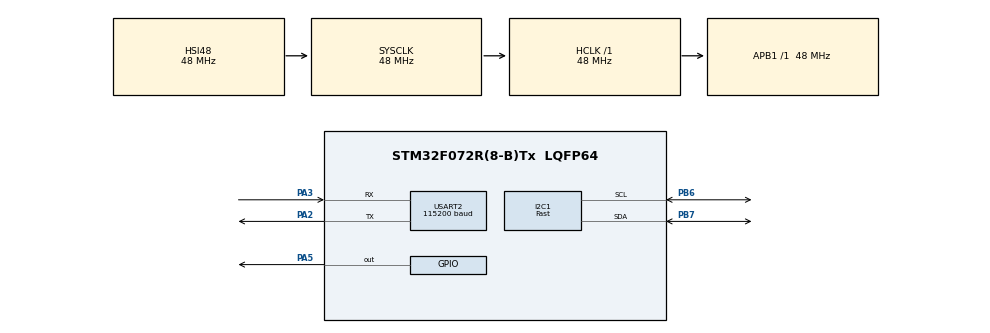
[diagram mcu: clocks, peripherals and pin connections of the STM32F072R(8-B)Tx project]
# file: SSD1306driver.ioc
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Dma.I2C1_RX.2.Direction=DMA_PERIPH_TO_MEMORY
Dma.I2C1_RX.2.Instance=DMA1_Channel3
Dma.I2C1_RX.2.MemDataAlignment=DMA_MDATAALIGN_BYTE
Dma.I2C1_RX.2.MemInc=DMA_MINC_ENABLE
Dma.I2C1_RX.2.Mode=DMA_NORMAL
Dma.I2C1_RX.2.PeriphDataAlignment=DMA_PDATAALIGN_BYTE
Dma.I2C1_RX.2.PeriphInc=DMA_PINC_DISABLE
Dma.I2C1_RX.2.Priority=DMA_PRIORITY_LOW
Dma.I2C1_TX.1.Direction=DMA_MEMORY_TO_PERIPH
Dma.I2C1_TX.1.Instance=DMA1_Channel2
Dma.I2C1_TX.1.MemDataAlignment=DMA_MDATAALIGN_BYTE
Dma.I2C1_TX.1.MemInc=DMA_MINC_ENABLE
Dma.I2C1_TX.1.Mode=DMA_NORMAL
Dma.I2C1_TX.1.PeriphDataAlignment=DMA_PDATAALIGN_BYTE
Dma.I2C1_TX.1.PeriphInc=DMA_PINC_DISABLE
Dma.I2C1_TX.1.Priority=DMA_PRIORITY_LOW
Dma.Request0=USART2_RX
Dma.Request1=I2C1_TX
Dma.Request2=I2C1_RX
Dma.USART2_RX.0.Direction=DMA_PERIPH_TO_MEMORY
Dma.USART2_RX.0.Instance=DMA1_Channel5
Dma.USART2_RX.0.MemDataAlignment=DMA_MDATAALIGN_BYTE
Dma.USART2_RX.0.MemInc=DMA_MINC_ENABLE
Dma.USART2_RX.0.Mode=DMA_NORMAL
Dma.USART2_RX.0.PeriphDataAlignment=DMA_PDATAALIGN_BYTE
Dma.USART2_RX.0.PeriphInc=DMA_PINC_DISABLE
Dma.USART2_RX.0.Priority=DMA_PRIORITY_LOW
I2C1.I2C_Speed_Mode=I2C_Fast
I2C1.Timing=0x0000020B
Mcu.Family=STM32F0
Mcu.Name=STM32F072R(8-B)Tx
Mcu.Package=LQFP64
NVIC.DMA1_Channel2_3_IRQn=true\:0\:0\:false\:false\:true\:false\:true
NVIC.DMA1_Channel4_5_6_7_IRQn=true\:0\:0\:false\:false\:true\:false\:true
NVIC.USART2_IRQn=true\:0\:0\:false\:false\:true\:true\:true
PA2.Mode=Asynchronous
PA2.Signal=USART2_TX
PA3.Mode=Asynchronous
PA3.Signal=USART2_RX
PA5.Signal=GPIO_Output
PB6.GPIO_FM6=SYSCFG_CFGR1_I2C_FMP_PB6
PB6.Mode=I2C
PB6.Signal=I2C1_SCL
PB7.GPIO_FM7=SYSCFG_CFGR1_I2C_FMP_PB7
PB7.Mode=I2C
PB7.Signal=I2C1_SDA
ProjectManager.HeapSize=0x200
ProjectManager.StackSize=0x400
ProjectManager.TargetToolchain=Makefile
RCC.AHBFreq_Value=48000000
RCC.APB1Freq_Value=48000000
RCC.APB1TimFreq_Value=48000000
RCC.HCLKFreq_Value=48000000
RCC.SYSCLKFreq_VALUE=48000000
RCC.SYSCLKSource=RCC_SYSCLKSOURCE_HSI48
USART2.BaudRate=115200
USART2.VirtualMode-Asynchronous=VM_ASYNC
board=custom

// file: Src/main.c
/* USER CODE BEGIN Header */
/**
	******************************************************************************
	* @file           : main.c
	* @brief          : Main program body
	******************************************************************************
	* @attention
	*
	* <h2><center>&copy; Copyright (c) 2020 STMicroelectronics.
	* All rights reserved.</center></h2>
	*
	* This software component is licensed by ST under BSD 3-Clause license,
	* the "License"; You may not use this file except in compliance with the
	* License. You may obtain a copy of the License at:
	*                        opensource.org/licenses/BSD-3-Clause
	*
	******************************************************************************
	*/
/* USER CODE END Header */

#include "main.h"

I2C_HandleTypeDef hi2c1;
DMA_HandleTypeDef hdma_i2c1_tx;
DMA_HandleTypeDef hdma_i2c1_rx;

UART_HandleTypeDef huart2;
DMA_HandleTypeDef hdma_usart2_rx;

void SystemClock_Config(void);
static void MX_GPIO_Init(void);
static void MX_DMA_Init(void);
static void MX_I2C1_Init(void);
static void MX_USART2_UART_Init(void);

int main(void)
{

  /* MCU Configuration--------------------------------------------------------*/

  /* Reset of all peripherals, Initializes the Flash interface and the Systick. */
  HAL_Init();

  /* Configure the system clock */
  SystemClock_Config();

  /* Initialize all configured peripherals */
  MX_GPIO_Init();
  MX_DMA_Init();
  MX_I2C1_Init();
  MX_USART2_UART_Init();
  /* USER CODE BEGIN 2 */
  SSD1306_init(&hi2c1);
  /* USER CODE END 2 */

  /* Infinite loop */
	while (1)
	{

	}
}

void SystemClock_Config(void)
{
  RCC_OscInitTypeDef RCC_OscInitStruct = {0};
  RCC_ClkInitTypeDef RCC_ClkInitStruct = {0};
  RCC_PeriphCLKInitTypeDef PeriphClkInit = {0};

  /** Initializes the CPU, AHB and APB busses clocks
  */
  RCC_OscInitStruct.OscillatorType = RCC_OSCILLATORTYPE_HSI|RCC_OSCILLATORTYPE_HSI48;
  RCC_OscInitStruct.HSIState = RCC_HSI_ON;
  RCC_OscInitStruct.HSI48State = RCC_HSI48_ON;
  RCC_OscInitStruct.HSICalibrationValue = RCC_HSICALIBRATION_DEFAULT;
  RCC_OscInitStruct.PLL.PLLState = RCC_PLL_NONE;
  if (HAL_RCC_OscConfig(&RCC_OscInitStruct) != HAL_OK)
  {
    Error_Handler();
  }
  /** Initializes the CPU, AHB and APB busses clocks
  */
  RCC_ClkInitStruct.ClockType = RCC_CLOCKTYPE_HCLK|RCC_CLOCKTYPE_SYSCLK
                              |RCC_CLOCKTYPE_PCLK1;
  RCC_ClkInitStruct.SYSCLKSource = RCC_SYSCLKSOURCE_HSI48;
  RCC_ClkInitStruct.AHBCLKDivider = RCC_SYSCLK_DIV1;
  RCC_ClkInitStruct.APB1CLKDivider = RCC_HCLK_DIV1;

  if (HAL_RCC_ClockConfig(&RCC_ClkInitStruct, FLASH_LATENCY_1) != HAL_OK)
  {
    Error_Handler();
  }
  PeriphClkInit.PeriphClockSelection = RCC_PERIPHCLK_USART2|RCC_PERIPHCLK_I2C1;
  PeriphClkInit.Usart2ClockSelection = RCC_USART2CLKSOURCE_PCLK1;
  PeriphClkInit.I2c1ClockSelection = RCC_I2C1CLKSOURCE_HSI;
  if (HAL_RCCEx_PeriphCLKConfig(&PeriphClkInit) != HAL_OK)
  {
    Error_Handler();
  }
}

static void MX_I2C1_Init(void)
{

  hi2c1.Instance = I2C1;
  hi2c1.Init.Timing = 0x0000020B;
  hi2c1.Init.OwnAddress1 = 0;
  hi2c1.Init.AddressingMode = I2C_ADDRESSINGMODE_7BIT;
  hi2c1.Init.DualAddressMode = I2C_DUALADDRESS_DISABLE;
  hi2c1.Init.OwnAddress2 = 0;
  hi2c1.Init.OwnAddress2Masks = I2C_OA2_NOMASK;
  hi2c1.Init.GeneralCallMode = I2C_GENERALCALL_DISABLE;
  hi2c1.Init.NoStretchMode = I2C_NOSTRETCH_DISABLE;
  if (HAL_I2C_Init(&hi2c1) != HAL_OK)
  {
    Error_Handler();
  }
  /** Configure Analogue filter
  */
  if (HAL_I2CEx_ConfigAnalogFilter(&hi2c1, I2C_ANALOGFILTER_ENABLE) != HAL_OK)
  {
    Error_Handler();
  }
  /** Configure Digital filter
  */
  if (HAL_I2CEx_ConfigDigitalFilter(&hi2c1, 0) != HAL_OK)
  {
    Error_Handler();
  }

}

static void MX_USART2_UART_Init(void)
{

  huart2.Instance = USART2;
  huart2.Init.BaudRate = 115200;
  huart2.Init.WordLength = UART_WORDLENGTH_8B;
  huart2.Init.StopBits = UART_STOPBITS_1;
  huart2.Init.Parity = UART_PARITY_NONE;
  huart2.Init.Mode = UART_MODE_TX_RX;
  huart2.Init.HwFlowCtl = UART_HWCONTROL_NONE;
  huart2.Init.OverSampling = UART_OVERSAMPLING_16;
  huart2.Init.OneBitSampling = UART_ONE_BIT_SAMPLE_DISABLE;
  huart2.AdvancedInit.AdvFeatureInit = UART_ADVFEATURE_NO_INIT;
  if (HAL_UART_Init(&huart2) != HAL_OK)
  {
    Error_Handler();
  }

}

static void MX_DMA_Init(void)
{

  /* DMA controller clock enable */
  __HAL_RCC_DMA1_CLK_ENABLE();

  /* DMA interrupt init */
  /* DMA1_Channel2_3_IRQn interrupt configuration */
  HAL_NVIC_SetPriority(DMA1_Channel2_3_IRQn, 0, 0);
  HAL_NVIC_EnableIRQ(DMA1_Channel2_3_IRQn);
  /* DMA1_Channel4_5_6_7_IRQn interrupt configuration */
  HAL_NVIC_SetPriority(DMA1_Channel4_5_6_7_IRQn, 0, 0);
  HAL_NVIC_EnableIRQ(DMA1_Channel4_5_6_7_IRQn);

}

static void MX_GPIO_Init(void)
{
  GPIO_InitTypeDef GPIO_InitStruct = {0};

  /* GPIO Ports Clock Enable */
  __HAL_RCC_GPIOA_CLK_ENABLE();
  __HAL_RCC_GPIOB_CLK_ENABLE();

  /*Configure GPIO pin Output Level */
  HAL_GPIO_WritePin(GPIOA, GPIO_PIN_5, GPIO_PIN_RESET);

  /*Configure GPIO pin : PA5 */
  GPIO_InitStruct.Pin = GPIO_PIN_5;
  GPIO_InitStruct.Mode = GPIO_MODE_OUTPUT_PP;
  GPIO_InitStruct.Pull = GPIO_NOPULL;
  GPIO_InitStruct.Speed = GPIO_SPEED_FREQ_LOW;
  HAL_GPIO_Init(GPIOA, &GPIO_InitStruct);

}

void Error_Handler(void)
{
}

/************************ (C) COPYRIGHT STMicroelectronics *****END OF FILE****/
